# PIC32MX270F256D register map
Registers are 32-bit, access not given, reset 0x0 unless marked. A register's access mark holds for its fields unless they carry their own. Offsets are from the block's base; [hi:lo] are bit positions; {n}, {i} and the like mark numbered series; 'fields as' and 'values as' point back to an identical list.

## NVM — NVM peripheral
Base 0xBF80F400
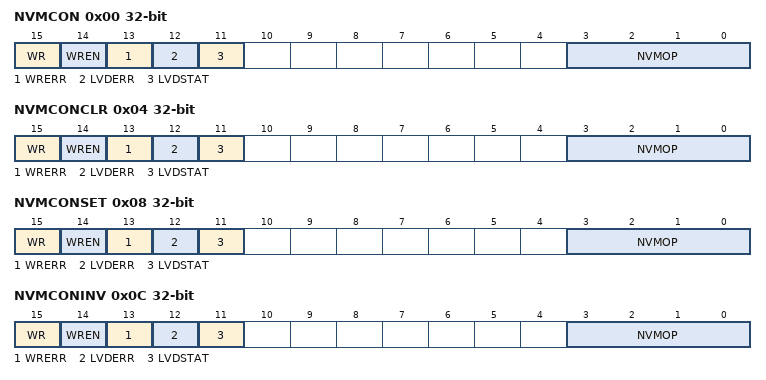
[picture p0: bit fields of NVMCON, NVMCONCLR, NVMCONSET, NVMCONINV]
0x00 NVMCON
  [15] WR, [14] WREN, [13] WRERR, [12] LVDERR, [11] LVDSTAT, [3:0] NVMOP
0x04 NVMCONCLR
  fields as NVMCON
0x08 NVMCONSET
  fields as NVMCON
0x0C NVMCONINV
  fields as NVMCON
0x10 NVMKEY
0x20 NVMADDR
0x24 NVMADDRCLR
  [31:0] NVMADDR
0x28 NVMADDRSET
  [31:0] NVMADDR
0x2C NVMADDRINV
  [31:0] NVMADDR
0x30 NVMDATA
0x40 NVMSRCADDR

## RCON — RCON peripheral
Base 0xBF80F600
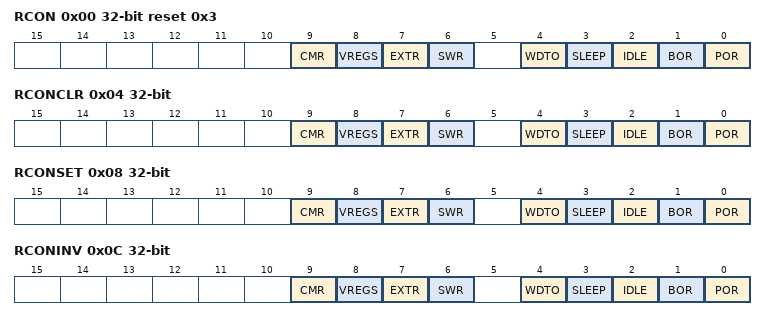
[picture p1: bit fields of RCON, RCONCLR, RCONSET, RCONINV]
0x00 RCON reset 0x3
  [9] CMR, [8] VREGS, [7] EXTR, [6] SWR, [4] WDTO, [3] SLEEP, [2] IDLE, [1] BOR, [0] POR
0x04 RCONCLR
  fields as RCON
0x08 RCONSET
  fields as RCON
0x0C RCONINV
  fields as RCON
0x10 RSWRST
  [0] SWRST
0x14 RSWRSTCLR
  [0] SWRST
0x18 RSWRSTSET
  [0] SWRST
0x1C RSWRSTINV
  [0] SWRST

## PPS — PPS peripheral
Base 0xBF80FA04
0x00 INT1R
  [3:0] INT1R
0x04 INT2R
  [3:0] INT2R
0x08 INT3R
  [3:0] INT3R
0x0C INT4R
  [3:0] INT4R
{0xC+4i} T{i}CKR (i=2..5)
  [3:0] T{i}CKR
{0x20+4i} IC{i}R (i=1..5)
  [3:0] IC{i}R
0x44 OCFAR
  [3:0] OCFAR
0x48 OCFBR
  [3:0] OCFBR
0x4C U1RXR
  [3:0] U1RXR
0x50 U1CTSR
  [3:0] U1CTSR
0x54 U2RXR
  [3:0] U2RXR
0x58 U2CTSR
  [3:0] U2CTSR
0x80 SDI1R
  [3:0] SDI1R
0x84 SS1R
  [3:0] SS1R
0x8C SDI2R
  [3:0] SDI2R
0x90 SS2R
  [3:0] SS2R
0xB4 REFCLKIR
  [3:0] REFCLKIR
{0xFC+4i} RPA{i}R (i=0..4)
  [3:0] RPA{i}R
0x11C RPA8R
  [3:0] RPA8R
0x120 RPA9R
  [3:0] RPA9R
{0x128+4i} RPB{i}R (i=0..5)
  [3:0] RPB{i}R
{0x128+4i} RPB{i}R (i=7..11)
  [3:0] RPB{i}R
{0x128+4i} RPB{i}R (i=13..15)
  [3:0] RPB{i}R
{0x168+4i} RPC{i}R (i=0..9)
  [3:0] RPC{i}R

## BMX — BMX peripheral
Base 0xBF882000
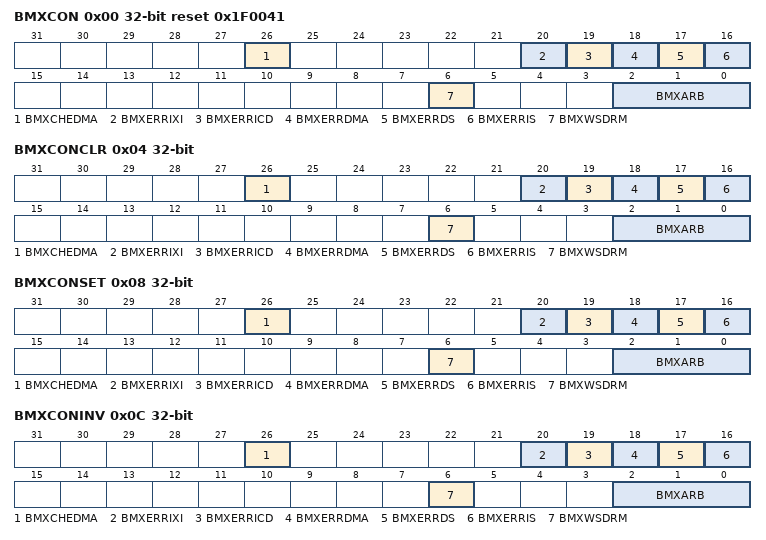
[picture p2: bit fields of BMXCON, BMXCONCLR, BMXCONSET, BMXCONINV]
0x00 BMXCON reset 0x1F0041
  [26] BMXCHEDMA, [20] BMXERRIXI, [19] BMXERRICD, [18] BMXERRDMA, [17] BMXERRDS, [16] BMXERRIS, [6] BMXWSDRM, [2:0] BMXARB
0x04 BMXCONCLR
  fields as BMXCON
0x08 BMXCONSET
  fields as BMXCON
0x0C BMXCONINV
  fields as BMXCON
0x10 BMXDKPBA
0x14 BMXDKPBACLR
  [31:0] BMXDKPBA
0x18 BMXDKPBASET
  [31:0] BMXDKPBA
0x1C BMXDKPBAINV
  [31:0] BMXDKPBA
0x20 BMXDUDBA
0x24 BMXDUDBACLR
  [31:0] BMXDUDBA
0x28 BMXDUDBASET
  [31:0] BMXDUDBA
0x2C BMXDUDBAINV
  [31:0] BMXDUDBA
0x30 BMXDUPBA
0x34 BMXDUPBACLR
  [31:0] BMXDUPBA
0x38 BMXDUPBASET
  [31:0] BMXDUPBA
0x3C BMXDUPBAINV
  [31:0] BMXDUPBA
0x40 BMXDRMSZ reset 0x20000
0x50 BMXPUPBA
0x54 BMXPUPBACLR
  [31:0] BMXPUPBA
0x58 BMXPUPBASET
  [31:0] BMXPUPBA
0x5C BMXPUPBAINV
  [31:0] BMXPUPBA
0x60 BMXPFMSZ reset 0x80000
0x70 BMXBOOTSZ reset 0x3000

## DMAC — DMAC peripheral
Base 0xBF883000
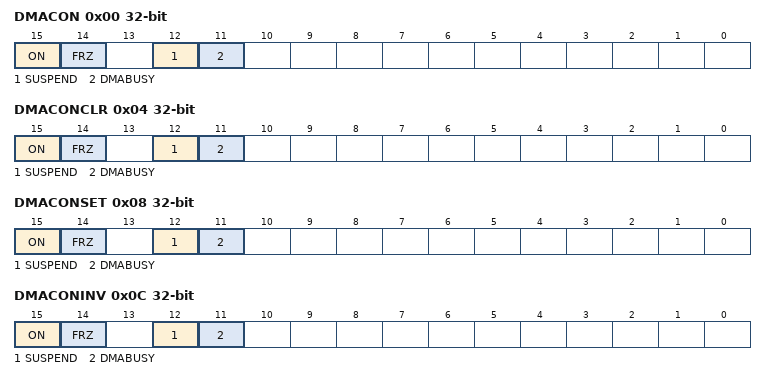
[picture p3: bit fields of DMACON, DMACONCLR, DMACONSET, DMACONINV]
0x00 DMACON
  [15] ON, [14] FRZ, [12] SUSPEND, [11] DMABUSY
0x04 DMACONCLR
  [15] ON, [14] FRZ, [12] SUSPEND, [11] DMABUSY
0x08 DMACONSET
  [15] ON, [14] FRZ, [12] SUSPEND, [11] DMABUSY
0x0C DMACONINV
  [15] ON, [14] FRZ, [12] SUSPEND, [11] DMABUSY
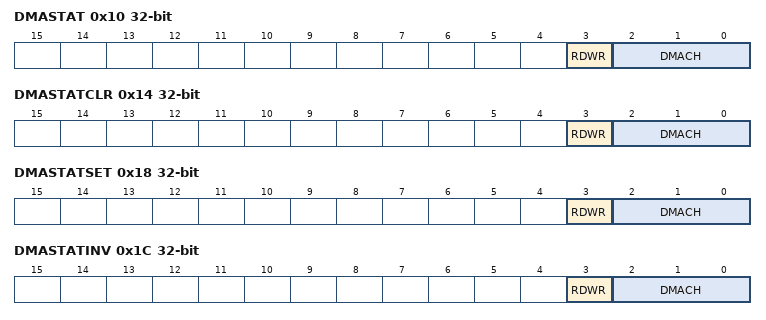
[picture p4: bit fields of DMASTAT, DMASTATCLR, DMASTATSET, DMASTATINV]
0x10 DMASTAT
  [3] RDWR, [2:0] DMACH
0x14 DMASTATCLR
  [3] RDWR, [2:0] DMACH
0x18 DMASTATSET
  [3] RDWR, [2:0] DMACH
0x1C DMASTATINV
  [3] RDWR, [2:0] DMACH
0x20 DMAADDR
0x24 DMAADDRCLR
  [31:0] DMAADDR
0x28 DMAADDRSET
  [31:0] DMAADDR
0x2C DMAADDRINV
  [31:0] DMAADDR
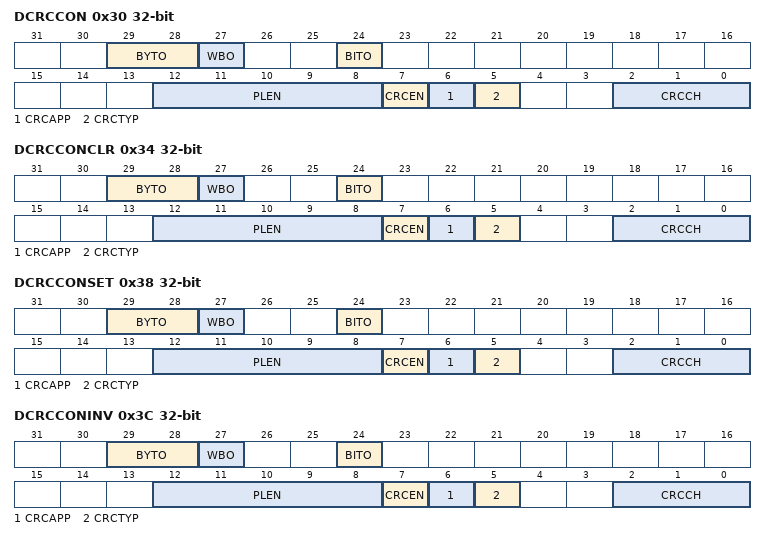
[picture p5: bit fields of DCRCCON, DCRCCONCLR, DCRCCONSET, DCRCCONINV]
0x30 DCRCCON
  [29:28] BYTO, [27] WBO, [24] BITO, [12:8] PLEN, [7] CRCEN, [6] CRCAPP, [5] CRCTYP, [2:0] CRCCH
0x34 DCRCCONCLR
  fields as DCRCCON
0x38 DCRCCONSET
  fields as DCRCCON
0x3C DCRCCONINV
  fields as DCRCCON
0x40 DCRCDATA
0x44 DCRCDATACLR
  [31:0] DCRCDATA
0x48 DCRCDATASET
  [31:0] DCRCDATA
0x4C DCRCDATAINV
  [31:0] DCRCDATA
0x50 DCRCXOR
0x54 DCRCXORCLR
  [31:0] DCRCXOR
0x58 DCRCXORSET
  [31:0] DCRCXOR
0x5C DCRCXORINV
  [31:0] DCRCXOR

## DMAC0 — DMAC0 peripheral
Base 0xBF883060
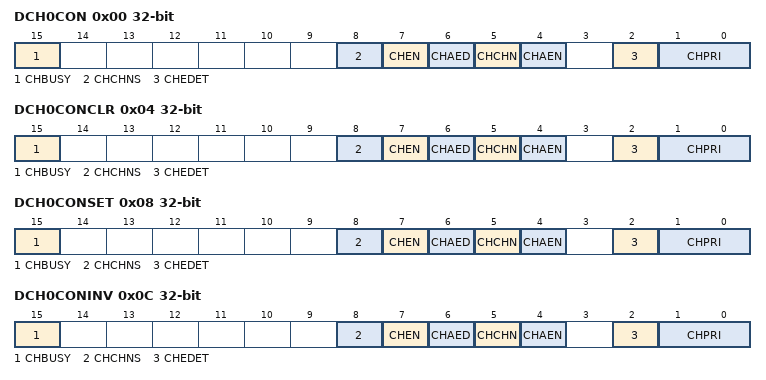
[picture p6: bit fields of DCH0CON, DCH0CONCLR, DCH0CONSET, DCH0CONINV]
0x00 DCH0CON
  [15] CHBUSY, [8] CHCHNS, [7] CHEN, [6] CHAED, [5] CHCHN, [4] CHAEN, [2] CHEDET, [1:0] CHPRI
0x04 DCH0CONCLR
  fields as DCH0CON
0x08 DCH0CONSET
  fields as DCH0CON
0x0C DCH0CONINV
  fields as DCH0CON
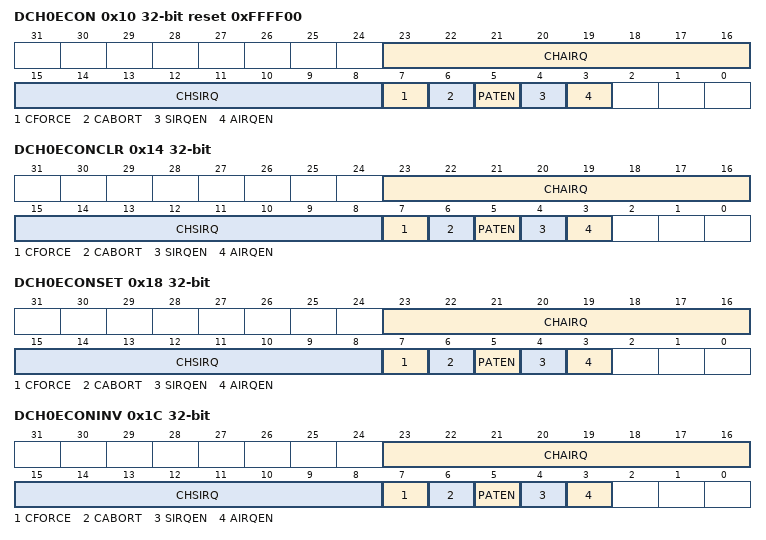
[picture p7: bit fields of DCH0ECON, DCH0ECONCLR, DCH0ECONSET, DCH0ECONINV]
0x10 DCH0ECON reset 0xFFFF00
  [23:16] CHAIRQ, [15:8] CHSIRQ, [7] CFORCE, [6] CABORT, [5] PATEN, [4] SIRQEN, [3] AIRQEN
0x14 DCH0ECONCLR
  fields as DCH0ECON
0x18 DCH0ECONSET
  fields as DCH0ECON
0x1C DCH0ECONINV
  fields as DCH0ECON
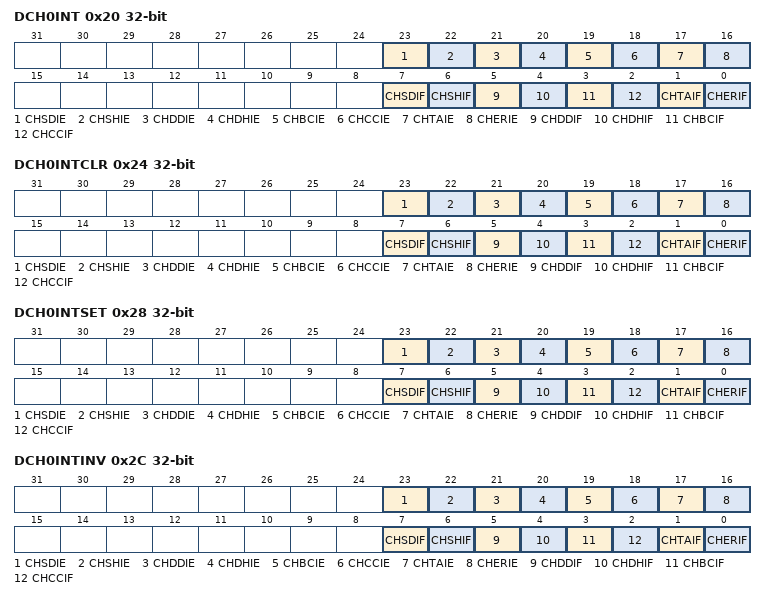
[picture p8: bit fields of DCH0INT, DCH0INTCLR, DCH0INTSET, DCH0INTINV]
0x20 DCH0INT
  [23] CHSDIE, [22] CHSHIE, [21] CHDDIE, [20] CHDHIE, [19] CHBCIE, [18] CHCCIE, [17] CHTAIE, [16] CHERIE, [7] CHSDIF, [6] CHSHIF, [5] CHDDIF, [4] CHDHIF, [3] CHBCIF, [2] CHCCIF, [1] CHTAIF, [0] CHERIF
0x24 DCH0INTCLR
  fields as DCH0INT
0x28 DCH0INTSET
  fields as DCH0INT
0x2C DCH0INTINV
  fields as DCH0INT
0x30 DCH0SSA
0x34 DCH0SSACLR
  [31:0] DCH0SSA
0x38 DCH0SSASET
  [31:0] DCH0SSA
0x3C DCH0SSAINV
  [31:0] DCH0SSA
0x40 DCH0DSA
0x44 DCH0DSACLR
  [31:0] DCH0DSA
0x48 DCH0DSASET
  [31:0] DCH0DSA
0x4C DCH0DSAINV
  [31:0] DCH0DSA
0x50 DCH0SSIZ
  [15:0] CHSSIZ
0x54 DCH0SSIZCLR
  [15:0] CHSSIZ
0x58 DCH0SSIZSET
  [15:0] CHSSIZ
0x5C DCH0SSIZINV
  [15:0] CHSSIZ
0x60 DCH0DSIZ
  [15:0] CHDSIZ
0x64 DCH0DSIZCLR
  [15:0] CHDSIZ
0x68 DCH0DSIZSET
  [15:0] CHDSIZ
0x6C DCH0DSIZINV
  [15:0] CHDSIZ
0x70 DCH0SPTR
  [15:0] CHSPTR
0x74 DCH0SPTRCLR
  [15:0] CHSPTR
0x78 DCH0SPTRSET
  [15:0] CHSPTR
0x7C DCH0SPTRINV
  [15:0] CHSPTR
0x80 DCH0DPTR
  [15:0] CHDPTR
0x84 DCH0DPTRCLR
  [15:0] CHDPTR
0x88 DCH0DPTRSET
  [15:0] CHDPTR
0x8C DCH0DPTRINV
  [15:0] CHDPTR
0x90 DCH0CSIZ
  [15:0] CHCSIZ
0x94 DCH0CSIZCLR
  [15:0] CHCSIZ
0x98 DCH0CSIZSET
  [15:0] CHCSIZ
0x9C DCH0CSIZINV
  [15:0] CHCSIZ
0xA0 DCH0CPTR
  [15:0] CHCPTR
0xA4 DCH0CPTRCLR
  [15:0] CHCPTR
0xA8 DCH0CPTRSET
  [15:0] CHCPTR
0xAC DCH0CPTRINV
  [15:0] CHCPTR
0xB0 DCH0DAT
  [7:0] DCHPDAT
0xB4 DCH0DATCLR
  [7:0] DCHPDAT
0xB8 DCH0DATSET
  [7:0] DCHPDAT
0xBC DCH0DATINV
  [7:0] DCHPDAT
